# DA14682 register map
Vendor: Dialog; Series: DA14682; File version: 1.2
CPU: CM0 r1p0, little endian, MPU, FPU, 3 interrupt priority bits
Registers are 16-bit, read-write, reset 0x0 unless marked. A register's access mark holds for its fields unless they carry their own. Offsets are from the block's base; [hi:lo] are bit positions; {n}, {i} and the like mark numbered series.

## BLE — BLE registers
Base 0x40000000
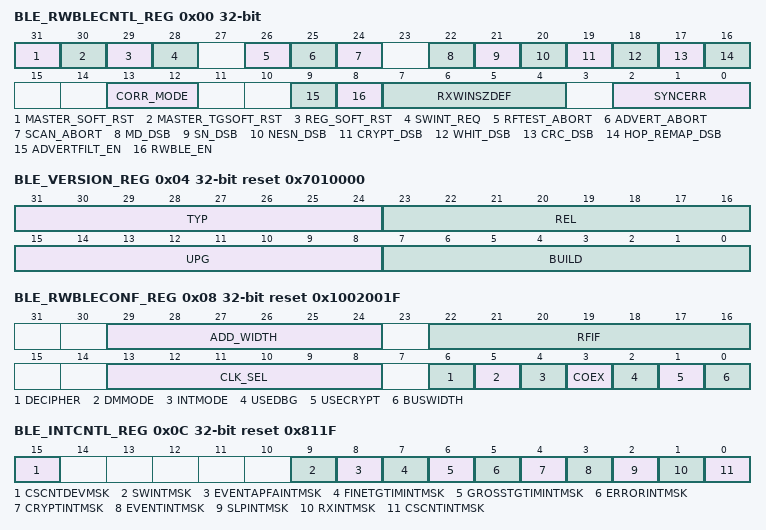
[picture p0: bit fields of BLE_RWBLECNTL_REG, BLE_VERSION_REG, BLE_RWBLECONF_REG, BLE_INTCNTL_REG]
0x00 BLE_RWBLECNTL_REG 32-bit (reset mask 0x7FFFFFFF) — BLE Control register
  [31] MASTER_SOFT_RST wo — Reset the complete BLE Core except registers and timing generator, when written with a 1. Resets at 0 when action is performed. No action happens if it is written with 0.
  [30] MASTER_TGSOFT_RST wo — Reset the timing generator, when written with a 1. Resets at 0 when action is performed. No action happens if it is written with 0.
  [29] REG_SOFT_RST — Reset the complete register block, when written with a 1. Resets at 0 when action is performed. No action happens if it is written with 0. Note that INT STAT will not be cleared, so the user should also write to BLE_INTACK_REG after the SW Reset
  [28] SWINT_REQ wo — Forces the generation of ble_sw_irq when written with a 1, and proper masking is set. Resets at 0 when action is performed. No action happens if it is written with 0.
  [26] RFTEST_ABORT wo — Abort the current RF Testing defined as per CS-FORMAT when written with a 1. Resets at 0 when action is performed. No action happens if it is written with 0. Note that when RFTEST_ABORT is requested: 1) In case of infinite Tx, the Packet Controller FSM stops at the end of the current byte in process, and processes accordingly the packet CRC. 2) In case of Infinite Rx, the Packet Controller FSM either stops as the end of the current Packet reception (if Access address has been detected), or simply stop the processing switching off the RF.
  [25] ADVERT_ABORT wo — Abort the current Advertising event when written with a 1. Resets at 0 when action is performed. No action happens if it is written with 0.
  [24] SCAN_ABORT wo — Abort the current scan window when written with a 1. Resets at 0 when action is performed. No action happens if it is written with 0.
  [22] MD_DSB — 0: Normal operation of MD bits management 1: Allow a single Tx/Rx exchange whatever the MD bits are. value forced by SW from Tx Descriptorvalue just saved in Rx Descriptor during reception
  [21] SN_DSB — 0: Normal operation of Sequence number 1: Sequence Number Management disabled: value forced by SW from Tx Descriptorvalue ignored in Rx, where no SN error reported.
  [20] NESN_DSB — 0: Normal operation of Acknowledge 1: Acknowledge scheme disabled: value forced by SW from Tx Descriptorvalue ignored in Rx, where no NESN error reported.
  [19] CRYPT_DSB — 0: Normal operation. Encryption / Decryption enabled. 1: Encryption / Decryption disabled. Note that if CS-CRYPT_EN is set, then MIC is generated, and only data encryption is disabled, meaning data sent are plain data.
  [18] WHIT_DSB — 0: Normal operation. Whitening enabled. 1: Whitening disabled.
  [17] CRC_DSB — 0: Normal operation. CRC removed from data stream. 1: CRC stripping disabled on Rx packets, CRC replaced by 0x000 in Tx.
  [16] HOP_REMAP_DSB — 0: Normal operation. Frequency Hopping Remapping algorithm enabled. 1: Frequency Hopping Remapping algorithm disabled
  [13:12] CORR_MODE — Defines correlation mode 00: Correlates onto Access Address 01: Correlates onto half preamble and Access Address 10: Correlates onto full preamble and Access Address 11: n/a
  [9] ADVERTFILT_EN — Advertising Channels Error Filtering Enable control 0: RW-BLE Core reports all errors to RW-BLE Software 1: RW-BLE Core reports only correctly received packet, without error to RW-BLE Software
  [8] RWBLE_EN — 0: Disable RW-BLE Core Exchange Table pre-fetch mechanism. 1: Enable RW-BLE Core Exchange table pre-fetch mechanism.
  [7:4] RXWINSZDEF — Default Rx Window size in us. Used when device: is master connectedperforms its second receipt.0 is not a valid value. Recommended value is 10 (in decimal).
  [2:0] SYNCERR — Indicates the maximum number of errors allowed to recognize the synchronization word.
0x04 BLE_VERSION_REG 32-bit reset 0x7010000 (reset mask 0x7FFFFFFF) — Version register
  [31:24] TYP ro — BLE Core Type
  [23:16] REL ro — BLE Core version Major release number.
  [15:8] UPG ro — BLE Core upgrade Upgrade number.
  [7:0] BUILD ro — BLE Core Build Build number.
0x08 BLE_RWBLECONF_REG 32-bit reset 0x1002001F — Configuration register
  [29:24] ADD_WIDTH ro — Value of the RW_BLE_ADDRESS_WIDTH parameter concerted into binary.
  [22:16] RFIF ro — Radio Interface ID
  [13:8] CLK_SEL ro — Operating Frequency (in MHz)
  [6] DECIPHER ro — 0: AES deciphering not present
  [5] DMMODE ro — 0: RW-BLE Core is used as a standalone BLE device
  [4] INTMODE ro — 1: Interrupts are trigger level generated, i.e. stays active at 1 till acknowledgement
  [3] COEX ro — 1: WLAN Coexistence mechanism present
  [2] USEDBG ro — 1: Diagnostic port instantiated
  [1] USECRYPT ro — 1: AES-CCM Encryption block present
  [0] BUSWIDTH ro — Processor bus width: 1: 32 bits
0x0C BLE_INTCNTL_REG 32-bit reset 0x811F — Interrupt controller register
  [15] CSCNTDEVMSK — CSCNT interrupt mask during event. This bit allows to enable CSCNT interrupt generation during events (i.e. advertising, scanning, initiating, and connection) 0: CSCNT Interrupt not generated during events. 1: CSCNT Interrupt generated during events.
  [9] SWINTMSK — SW triggered interrupt Mask 0: Interrupt not generated 1: Interrupt generated
  [8] EVENTAPFAINTMSK — End of event / anticipated pre-fetch abort interrupt Mask 0: Interrupt not generated 1: Interrupt generated
  [7] FINETGTIMINTMSK — Fine Target Timer Mask 0: Interrupt not generated 1: Interrupt generated
  [6] GROSSTGTIMINTMSK — Gross Target Timer Mask 0: Interrupt not generated 1: Interrupt generated
  [5] ERRORINTMSK — Error Interrupt Mask 0: Interrupt not generated 1: Interrupt generated
  [4] CRYPTINTMSK — Encryption engine Interrupt Mask 0: Interrupt not generated 1: Interrupt generated
  [3] EVENTINTMSK — End of event Interrupt Mask 0: Interrupt not generated 1: Interrupt generated
  [2] SLPINTMSK — Sleep Mode Interrupt Mask 0: Interrupt not generated 1: Interrupt generated
  [1] RXINTMSK — Rx Interrupt Mask 0: Interrupt not generated 1: Interrupt generated
  [0] CSCNTINTMSK — 625us Base Time Interrupt Mask 0: Interrupt not generated 1: Interrupt generated
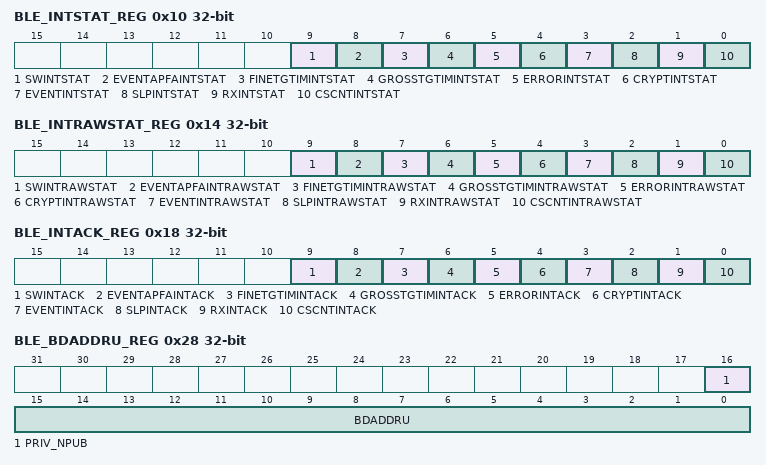
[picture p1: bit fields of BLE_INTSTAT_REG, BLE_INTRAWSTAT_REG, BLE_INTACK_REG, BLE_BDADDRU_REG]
0x10 BLE_INTSTAT_REG 32-bit — Interrupt status register
  [9] SWINTSTAT ro — SW triggered interrupt status 0: No SW triggered interrupt. 1: A SW triggered interrupt is pending
  [8] EVENTAPFAINTSTAT ro — End of event / Anticipated Pre-Fetch Abort interrupt status 0: No End of Event interrupt. 1: An End of Event interrupt is pending.
  [7] FINETGTIMINTSTAT ro — Masked Fine Target Timer Error interrupt status 0: No Fine Target Timer interrupt. 1: A Fine Target Timer interrupt is pending.
  [6] GROSSTGTIMINTSTAT ro — Masked Gross Target Timer interrupt status 0: No Gross Target Timer interrupt. 1: A Gross Target Timer interrupt is pending.
  [5] ERRORINTSTAT ro — Masked Error interrupt status 0: No Error interrupt. 1: An Error interrupt is pending.
  [4] CRYPTINTSTAT ro — Masked Encryption engine interrupt status 0: No Encryption / Decryption interrupt. 1: An Encryption / Decryption interrupt is pending.
  [3] EVENTINTSTAT ro — Masked End of Event interrupt status 0: No End of Advertising / Scanning / Connection interrupt. 1: An End of Advertising / Scanning / Connection interrupt is pending.
  [2] SLPINTSTAT ro — Masked Sleep interrupt status 0: No End of Sleep Mode interrupt. 1: An End of Sleep Mode interrupt is pending.
  [1] RXINTSTAT ro — Masked Packet Reception interrupt status 0: No Rx interrupt. 1: An Rx interrupt is pending.
  [0] CSCNTINTSTAT ro — Masked 625us base time reference interrupt status 0: No 625us Base Time interrupt. 1: A 625us Base Time interrupt is pending.
0x14 BLE_INTRAWSTAT_REG 32-bit — Interrupt raw status register
  [9] SWINTRAWSTAT ro — SW triggered interrupt raw status 0: No SW triggered interrupt. 1: A SW triggered interrupt is pending.
  [8] EVENTAPFAINTRAWSTAT ro — End of event / Anticipated Pre-Fetch Abort interrupt raw status 0: No End of Event interrupt. 1: An End of Event interrupt is pending.
  [7] FINETGTIMINTRAWSTAT ro — Fine Target Timer Error interrupt raw status 0: No Fine Target Timer interrupt. 1: A Fine Target Timer interrupt is pending.
  [6] GROSSTGTIMINTRAWSTAT ro — Gross Target Timer interrupt raw status 0: No Gross Target Timer interrupt. 1: A Gross Target Timer interrupt is pending.
  [5] ERRORINTRAWSTAT ro — Error interrupt raw status 0: No Error interrupt. 1: An Error interrupt is pending.
  [4] CRYPTINTRAWSTAT ro — Encryption engine interrupt raw status 0: No Encryption / Decryption interrupt. 1: An Encryption / Decryption interrupt is pending.
  [3] EVENTINTRAWSTAT ro — End of Event interrupt raw status 0: No End of Advertising / Scanning / Connection interrupt. 1: An End of Advertising / Scanning / Connection interrupt is pending.
  [2] SLPINTRAWSTAT ro — Sleep interrupt raw status 0: No End of Sleep Mode interrupt. 1: An End of Sleep Mode interrupt is pending.
  [1] RXINTRAWSTAT ro — Packet Reception interrupt raw status 0: No Rx interrupt. 1: An Rx interrupt is pending.
  [0] CSCNTINTRAWSTAT ro — 625us base time reference interrupt raw status 0: No 625us Base Time interrupt. 1: A 625us Base Time interrupt is pending.
0x18 BLE_INTACK_REG 32-bit — Interrupt acknowledge register
  [9] SWINTACK wo — SW triggered interrupt acknowledgement bit Software writing 1 acknowledges the SW triggered interrupt. This bit resets SWINTSTAT and SWINTRAWSTAT flags. Resets at 0 when action is performed
  [8] EVENTAPFAINTACK wo — End of event / Anticipated Pre-Fetch Abort interrupt acknowledgement bit Software writing 1 acknowledges the End of event / Anticipated Pre-Fetch Abort interrupt. This bit resets EVENTAPFAINTSTAT and EVENTAPFAINTRAWSTAT flags. Resets at 0 when action is performed
  [7] FINETGTIMINTACK wo — Fine Target Timer interrupt acknowledgement bit Software writing 1 acknowledges the Fine Timer interrupt. This bit resets FINETGTIMINTSTAT and FINETGTIMINTRAWSTAT flags. Resets at 0 when action is performed
  [6] GROSSTGTIMINTACK wo — Gross Target Timer interrupt acknowledgement bit Software writing 1 acknowledges the Gross Timer interrupt. This bit resets GROSSTGTIMINTSTAT and GROSSTGTIMINTRAWSTAT flags. Resets at 0 when action is performed
  [5] ERRORINTACK wo — Error interrupt acknowledgement bit Software writing 1 acknowledges the Error interrupt. This bit resets ERRORINTSTAT and ERRORINTRAWSTAT flags. Resets at 0 when action is performed
  [4] CRYPTINTACK wo — Encryption engine interrupt acknowledgement bit Software writing 1 acknowledges the Encryption engine interrupt. This bit resets CRYPTINTSTAT and CRYPTINTRAWSTAT flags. Resets at 0 when action is performed
  [3] EVENTINTACK wo — End of Event interrupt acknowledgment bit Software writing 1 acknowledges the End of Advertising / Scanning / Connection interrupt. This bit resets SLPINTSTAT and SLPINTRAWSTAT flags. Resets at 0 when action is performed
  [2] SLPINTACK wo — End of Deep Sleep interrupt acknowledgment bit Software writing 1 acknowledges the End of Sleep Mode interrupt. This bit resets SLPINTSTAT and SLPINTRAWSTAT flags. Resets at 0 when action is performed
  [1] RXINTACK wo — Packet Reception interrupt acknowledgment bit Software writing 1 acknowledges the Rx interrupt. This bit resets RXINTSTAT and RXINTRAWSTAT flags. Resets at 0 when action is performed
  [0] CSCNTINTACK wo — 625us base time reference interrupt acknowledgment bit Software writing 1 acknowledges the CLKN interrupt. This bit resets CLKINTSTAT and CLKINTRAWSTAT flags. Resets at 0 when action is performed
0x1C BLE_BASETIMECNT_REG 32-bit — Base time reference counter
  [26:0] BASETIMECNT ro — Value of the 625us base time reference counter. Updated each time SAMPCLK is written. Used by the SW in order to synchronize with the HW
0x20 BLE_FINETIMECNT_REG 32-bit — Fine time reference counter
  [9:0] FINECNT ro — Value of the current s fine time reference counter. Updated each time SAMPCLK is written. Used by the SW in order to synchronize with the HW, and obtain a more precise sleep duration
0x24 BLE_BDADDRL_REG 32-bit (reset mask 0x7FFFFFFF) — BLE device address LSB register
  [31:0] BDADDRL — Bluetooth Low Energy Device Address. LSB part.
0x28 BLE_BDADDRU_REG 32-bit — BLE device address MSB register
  [16] PRIV_NPUB — Bluetooth Low Energy Device Address privacy indicator 0: Public Bluetooth Device Address 1: Private Bluetooth Device Address
  [15:0] BDADDRU — Bluetooth Low Energy Device Address. MSB part.
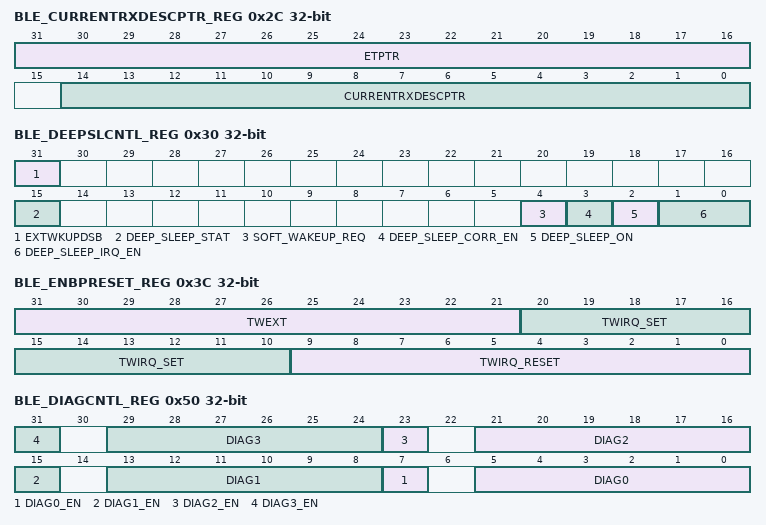
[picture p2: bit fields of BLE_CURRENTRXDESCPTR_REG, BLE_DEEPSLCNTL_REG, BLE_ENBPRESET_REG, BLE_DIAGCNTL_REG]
0x2C BLE_CURRENTRXDESCPTR_REG 32-bit (reset mask 0x7FFFFFFF) — Rx Descriptor Pointer for the Receive Buffer Chained List
  [31:16] ETPTR — Exchange Table Pointer that determines the starting point of the Exchange Table
  [14:0] CURRENTRXDESCPTR — Rx Descriptor Pointer that determines the starting point of the Receive Buffer Chained List
0x30 BLE_DEEPSLCNTL_REG 32-bit (reset mask 0x7FFFFFFF) — Deep-Sleep control register
  [31] EXTWKUPDSB — External Wake-Up disable 0: RW-BLE Core can be woken by external wake-up 1: RW-BLE Core cannot be woken up by external wake-up
  [15] DEEP_SLEEP_STAT ro — Indicator of current Deep Sleep clock mux status: 0: RW-BLE Core is not yet in Deep Sleep Mode 1: RW-BLE Core is in Deep Sleep Mode (only low_power_clk is running)
  [4] SOFT_WAKEUP_REQ — Wake Up Request from RW-BLE Software. Applies when system is in Deep Sleep Mode. It wakes up the RW-BLE Core when written with a 1. Resets at 0 when action is performed. No action happens if it is written with 0.
  [3] DEEP_SLEEP_CORR_EN — 625us base time reference integer and fractional part correction. Applies when system has been woken-up from Deep Sleep Mode. It enables Fine Counter and Base Time counter when written with a 1. Resets at 0 when action is performed. No action happens if it is written with 0.
  [2] DEEP_SLEEP_ON — 0: RW-BLE Core in normal active mode 1: Request RW-BLE Core to switch in deep sleep mode. This bit is reset on DEEP_SLEEP_STAT falling edge.
  [1:0] DEEP_SLEEP_IRQ_EN — Always set to "3" when DEEP_SLEEP_ON is set to "1". It controls the generation of BLE_WAKEUP_LP_IRQ.
0x34 BLE_DEEPSLWKUP_REG 32-bit (reset mask 0x7FFFFFFF) — Time (measured in Low Power clock cycles) in Deep Sleep Mode before waking-up the device
  [31:0] DEEPSLTIME — Determines the time in low_power_clk clock cycles to spend in Deep Sleep Mode before waking-up the device. This ensures a maximum of 37 hours and 16mn sleep mode capabilities at 32kHz. This ensures a maximum of 36 hours and 16mn sleep mode capabilities at 32.768kHz
0x38 BLE_DEEPSLSTAT_REG 32-bit (reset mask 0x7FFFFFFF) — Duration of the last deep sleep phase register
  [31:0] DEEPSLDUR ro — Actual duration of the last deep sleep phase measured in low_power_clk clock cycle. DEEPSLDUR is set to zero at the beginning of the deep sleep phase, and is incremented at each low_power_clk clock cycle until the end of the deep sleep phase.
0x3C BLE_ENBPRESET_REG 32-bit (reset mask 0x7FFFFFFF) — Time in low power oscillator cycles register
  [31:21] TWEXT — Minimum and recommended value is "TWIRQ_RESET + 1". In the case of wake-up due to an external wake-up request, TWEXT specifies the time delay in low power oscillator cycles to deassert BLE_WAKEUP_LP_IRQ. Refer also to GP_CONTROL_REG[BLE_WAKEUP_REQ]. Range is [0...64 ms] for 32kHz; [0...62.5 ms] for 32.768kHz
  [20:10] TWIRQ_SET — Minimum value is "TWIRQ_RESET + 1". Time in low power oscillator cycles to set BLE_WAKEUP_LP_IRQ before the BLE sleep timer expiration. Refer also to BLE_DEEPSLWKUP_REG[DEEPSLTIME]. Range is [0...64 ms] for 32kHz; [0...62.5 ms] for 32.768kHz
  [9:0] TWIRQ_RESET — Recommended value is 1. Time in low power oscillator cycles to reset BLE_WAKEUP_LP_IRQ before the BLE sleep timer expiration. Refer also to BLE_DEEPSLWKUP_REG[DEEPSLTIME]. Range is [0...32 ms] for 32kHz; [0...31.25 ms] for 32.768kHz.
0x40 BLE_FINECNTCORR_REG 32-bit — Phase correction value register
  [9:0] FINECNTCORR — Phase correction value for the 625us reference counter (i.e. Fine Counter) in us.
0x44 BLE_BASETIMECNTCORR_REG 32-bit — Base Time Counter
  [26:0] BASETIMECNTCORR — Base Time Counter correction value.
0x50 BLE_DIAGCNTL_REG 32-bit (reset mask 0x7FFFFFFF) — Diagnostics Register
  [8n+7] DIAG{n}_EN (n=0..3) — 0: Disable diagnostic port 0 output. All outputs are set to 0x0. 1: Enable diagnostic port 0 output.
  [8n+5:8n] DIAG{n} (n=0..3) — Only relevant when DIAG{n}_EN = 1. Selection of the outputs that must be driven to the diagnostic port BLE_DIAG{n}.
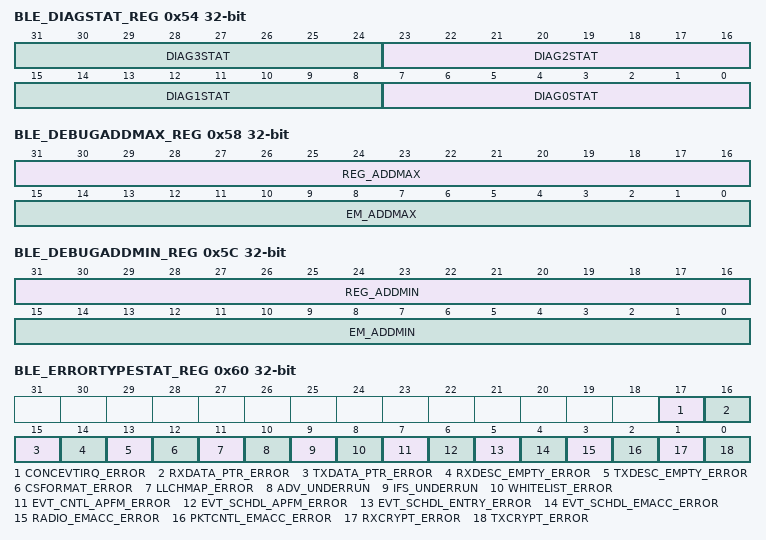
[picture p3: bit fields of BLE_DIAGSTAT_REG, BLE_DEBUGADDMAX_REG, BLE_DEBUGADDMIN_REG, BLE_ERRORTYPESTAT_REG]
0x54 BLE_DIAGSTAT_REG 32-bit (reset mask 0x7FFFFFFF) — Debug use only
  [8n+7:8n] DIAG{n}STAT ro (n=0..3) — Directly connected to ble_dbg{n}[7:0] output. Debug use only.
0x58 BLE_DEBUGADDMAX_REG 32-bit (reset mask 0x7FFFFFFF) — Upper limit for the memory zone
  [31:16] REG_ADDMAX — Upper limit for the Register zone indicated by the reg_inzone flag
  [15:0] EM_ADDMAX — Upper limit for the Exchange Memory zone indicated by the em_inzone flag
0x5C BLE_DEBUGADDMIN_REG 32-bit (reset mask 0x7FFFFFFF) — Lower limit for the memory zone
  [31:16] REG_ADDMIN — Lower limit for the Register zone indicated by the reg_inzone flag
  [15:0] EM_ADDMIN — Lower limit for the Exchange Memory zone indicated by the em_inzone flag
0x60 BLE_ERRORTYPESTAT_REG 32-bit — Error Type Status registers
  [17] CONCEVTIRQ_ERROR ro — Indicates whether two consecutive and concurrent ble_event_irq have been generated, and not acknowledged in time by the RW-BLE Software. 0: No error 1: Error occurred
  [16] RXDATA_PTR_ERROR ro — Indicates whether Rx data buffer pointer value programmed is null: this is a major programming failure. 0: No error 1: Error occurred
  [15] TXDATA_PTR_ERROR ro — Indicates whether Tx data buffer pointer value programmed is null during Advertising / Scanning / Initiating events, or during Master / Slave connections with non-null packet length: this is a major programming failure. 0: No error 1: Error occurred
  [14] RXDESC_EMPTY_ERROR ro — Indicates whether Rx Descriptor pointer value programmed in register is null: this is a major programming failure. 0: No error 1: Error occurred
  [13] TXDESC_EMPTY_ERROR ro — Indicates whether Tx Descriptor pointer value programmed in Control Structure is null during Advertising / Scanning / Initiating events: this is a major programming failure. 0: No error 1: Error occurred
  [12] CSFORMAT_ERROR ro — Indicates whether CS-FORMAT has been programmed with an invalid value: this is a major software programming failure. 0: No error 1: Error occurred
  [11] LLCHMAP_ERROR ro — Indicates Link Layer Channel Map error, happens when actual number of CS-LLCHMAP bit set to one is different from CS-NBCHGOOD at the beginning of Frequency Hopping process 0: No error 1: Error occurred
  [10] ADV_UNDERRUN ro — Indicates Advertising Interval Under run, occurs if time between two consecutive Advertising packet (in Advertising mode) is lower than the expected value. 0: No error 1: Error occurred
  [9] IFS_UNDERRUN ro — Indicates Inter Frame Space Under run, occurs if IFS time is not enough to update and read Control Structure/Descriptors, and/or White List parsing is not finished and/or Decryption time is too long to be finished on time 0: No error 1: Error occurred
  [8] WHITELIST_ERROR ro — Indicates White List Timeout error, occurs if White List parsing is not finished on time 0: No error 1: Error occurred
  [7] EVT_CNTL_APFM_ERROR ro — Indicates Anticipated Pre-Fetch Mechanism error: happens when 2 consecutive events are programmed, and when the first event is not completely finished while second pre-fetch instant is reached. 0: No error 1: Error occured
  [6] EVT_SCHDL_APFM_ERROR ro — Indicates Anticipated Pre-Fetch Mechanism error: happens when 2 consecutive events are programmed, and when the first event is not completely finished while second pre-fetch instant is reached. 0: No error 1: Error occured
  [5] EVT_SCHDL_ENTRY_ERROR ro — Indicates Event Scheduler faced Invalid timing programing on two consecutive ET entries (e.g first one with 624s offset and second one with no offset) 0: No error 1: Error occurred
  [4] EVT_SCHDL_EMACC_ERROR ro — Indicates Event Scheduler Exchange Memory access error, happens when Exchange Memory accesses are not served in time, and blocks the Exchange Table entry read 0: No error 1: Error occurred
  [3] RADIO_EMACC_ERROR ro — Indicates Radio Controller Exchange Memory access error, happens when Exchange Memory accesses are not served in time and data are corrupted. 0: No error 1: Error occurred
  [2] PKTCNTL_EMACC_ERROR ro — Indicates Packet Controller Exchange Memory access error, happens when Exchange Memory accesses are not served in time and Tx/Rx data are corrupted 0: No error 1: Error occurred
  [1] RXCRYPT_ERROR ro — Indicates real time decryption error, happens when AES-CCM decryption is too slow compared to Packet Controller requests. A 16-bytes block has to be decrypted prior the next block is received by the Packet Controller 0: No error 1: Error occurred
  [0] TXCRYPT_ERROR ro — Indicates Real Time encryption error, happens when AES-CCM encryption is too slow compared to Packet Controller requests. A 16-bytes block has to be encrypted and prepared on Packet Controller request, and needs to be ready before the Packet Controller has to send ti 0: No error 1: Error occurred
0x64 BLE_SWPROFILING_REG 32-bit (reset mask 0x7FFFFFFF) — Software Profiling register
  [31:0] SWPROFVAL — Software Profiling register: used by RW-BLE Software for profiling purpose: this value is copied on Diagnostic port
0x70 BLE_RADIOCNTL0_REG 32-bit reset 0x2 — Radio interface control register
  [4:2] field246rsv
0x74 BLE_RADIOCNTL1_REG 32-bit — Radio interface control register
  [20:16] XRFSEL — Extended radio selection field, Must be set to "2".
0x78 BLE_RADIOCNTL2_REG 32-bit (reset mask 0x7FFFFFFF) — Radio interface control register
0x7C BLE_RADIOCNTL3_REG 32-bit reset 0x40 (reset mask 0x7FFFFFFF) — Radio interface control register
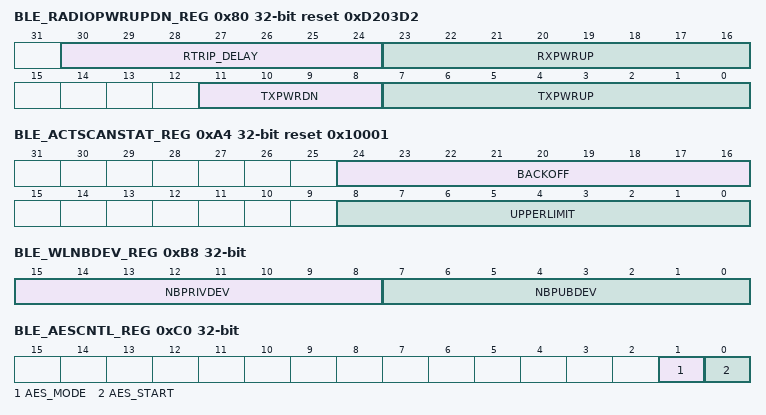
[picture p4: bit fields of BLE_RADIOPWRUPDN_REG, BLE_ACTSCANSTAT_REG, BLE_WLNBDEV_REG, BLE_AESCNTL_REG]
0x80 BLE_RADIOPWRUPDN_REG 32-bit reset 0xD203D2 — RX/TX power up/down phase register
  [30:24] RTRIP_DELAY — Defines round trip delay value. This value correspond to the addition of data latency in Tx and data latency in Rx. Value is in us
  [23:16] RXPWRUP — This register holds the length in s of the RX power up phase for the current radio device. Default value is 210us (reset value). Operating range depends on the selected radio.
  [11:8] TXPWRDN — This register extends the length in s of the TX power down phase for the current radio device. Default value is 3us (reset value). Operating range depends on the selected radio.
  [7:0] TXPWRUP — This register holds the length in s of the TX power up phase for the current radio device. Default value is 210us (reset value). Operating range depends on the selected radio.
0x90 BLE_ADVCHMAP_REG 32-bit reset 0x7 — Advertising Channel Map
  [2:0] ADVCHMAP — Advertising Channel Map, defined as per the advertising connection settings. Contains advertising channels index 37 to 39. If ADVCHMAP[i] equals: 0: Do not use data channel i+37. 1: Use data channel i+37.
0xA0 BLE_ADVTIM_REG 32-bit — Advertising Packet Interval
  [13:0] ADVINT — Advertising Packet Interval defines the time interval in between two ADV_xxx packet sent. Value is in us. Value to program depends on the used Advertising Packet type and the device filtering policy.
0xA4 BLE_ACTSCANSTAT_REG 32-bit reset 0x10001 — Active scan register
  [24:16] BACKOFF ro — Active scan mode back-off counter initialization value.
  [8:0] UPPERLIMIT ro — Active scan mode upper limit counter value.
0xB0 BLE_WLPUBADDPTR_REG 32-bit — Start address of public devices list
  [15:0] WLPUBADDPTR — Start address pointer of the public devices white list.
0xB4 BLE_WLPRIVADDPTR_REG 32-bit — Start address of private devices list
  [15:0] WLPRIVADDPTR — Start address pointer of the private devices white list.
0xB8 BLE_WLNBDEV_REG 32-bit — Devices in white list
  [15:8] NBPRIVDEV — Number of private devices in the white list.
  [7:0] NBPUBDEV — Number of public devices in the white list.
0xC0 BLE_AESCNTL_REG 32-bit — Start AES register
  [1] AES_MODE — 0: Cipher mode 1: Decipher mode
  [0] AES_START wo — Writing a 1 starts AES-128 ciphering/deciphering process. This bit is reset once the process is finished (i.e. ble_crypt_irq interrupt occurs, even masked)
0xC4 BLE_AESKEY31_0_REG 32-bit (reset mask 0x7FFFFFFF) — AES encryption key
  [31:0] AESKEY31_0 — AES encryption 128-bit key. Bit 31 down to 0
0xC8 BLE_AESKEY63_32_REG 32-bit (reset mask 0x7FFFFFFF) — AES encryption key
  [31:0] AESKEY63_32 — AES encryption 128-bit key. Bit 63 down to 32
0xCC BLE_AESKEY95_64_REG 32-bit (reset mask 0x7FFFFFFF) — AES encryption key
  [31:0] AESKEY95_64 — AES encryption 128-bit key. Bit 95 down to 64
0xD0 BLE_AESKEY127_96_REG 32-bit (reset mask 0x7FFFFFFF) — AES encryption key
  [31:0] AESKEY127_96 — AES encryption 128-bit key. Bit 127 down to 96
0xD4 BLE_AESPTR_REG 32-bit — Pointer to the block to encrypt/decrypt
  [15:0] AESPTR — Pointer to the memory zone where the block to cipher/decipher using AES-128 is stored.
0xD8 BLE_TXMICVAL_REG 32-bit (reset mask 0x7FFFFFFF) — AES / CCM plain MIC value
  [31:0] TXMICVAL ro — AES-CCM plain MIC value. Valid on when MIC has been calculated (in Tx)
0xDC BLE_RXMICVAL_REG 32-bit (reset mask 0x7FFFFFFF) — AES / CCM plain MIC value
  [31:0] RXMICVAL ro — AES-CCM plain MIC value. Valid on once MIC has been extracted from Rx packet.
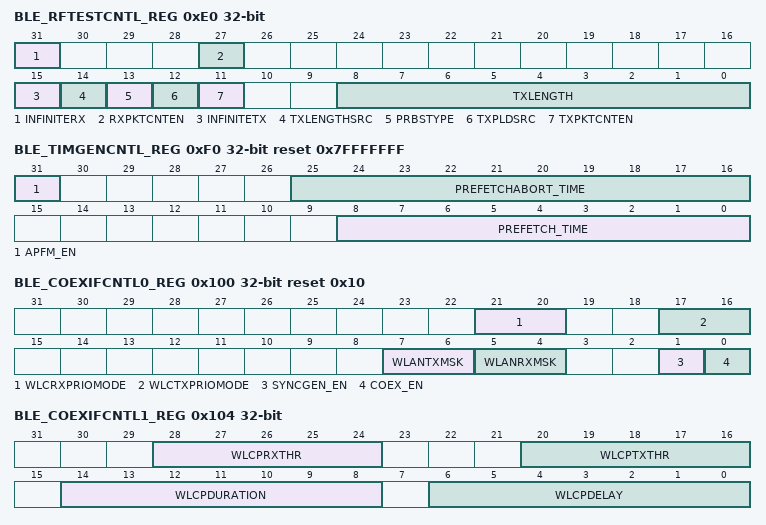
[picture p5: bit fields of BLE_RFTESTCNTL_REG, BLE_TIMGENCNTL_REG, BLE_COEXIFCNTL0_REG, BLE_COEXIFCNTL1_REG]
0xE0 BLE_RFTESTCNTL_REG 32-bit (reset mask 0x7FFFFFFF) — RF Testing Register
  [31] INFINITERX — Applicable in RF Test Mode only 0: Normal mode of operation 1: Infinite Rx window
  [27] RXPKTCNTEN — Applicable in RF Test Mode only 0: Rx packet count disabled 1: Rx packet count enabled, and reported in CS-RXCCMPKTCNT and RFTESTRXSTAT-RXPKTCNT on RF abort command
  [15] INFINITETX — Applicable in RF Test Mode only 0: Normal mode of operation. 1: Infinite Tx packet / Normal start of a packet but endless payload
  [14] TXLENGTHSRC — Applicable only in Tx/Rx RF Test mode 0: Normal mode of operation: TxDESC-TXADVLEN controls the Tx packet payload size 1: Uses RFTESTCNTL-TXLENGTH packet length (can support up to 512 bytes transmit)
  [13] PRBSTYPE — Applicable only in Tx/Rx RF Test mode 0: Tx Packet Payload are PRBS9 type 1: Tx Packet Payload are PRBS15 type
  [12] TXPLDSRC — Applicable only in Tx/Rx RF Test mode 0: Tx Packet Payload source is the Control Structure 1: Tx Packet Payload are PRBS generator
  [11] TXPKTCNTEN — Applicable in RF Test Mode only 0: Tx packet count disabled 1: Tx packet count enabled, and reported in CS-TXCCMPKTCNT and RFTESTTXSTAT-TXPKTCNT on RF abort command
  [8:0] TXLENGTH — Applicable only for Tx/Rx RF Test mode, and valid when RFTESTCNTL-TXLENGTHSRC = 1 Tx packet length in number of byte
0xE4 BLE_RFTESTTXSTAT_REG 32-bit (reset mask 0x7FFFFFFF) — RF Testing Register
  [31:0] TXPKTCNT ro — Reports number of transmitted packet during Test Modes. Value is valid if RFTESTCNTL-TXPKTCNTEN is set
0xE8 BLE_RFTESTRXSTAT_REG 32-bit (reset mask 0x7FFFFFFF) — RF Testing Register
  [31:0] RXPKTCNT ro — Reports number of correctly received packet during Test Modes (no sync error, no CRC error). Value is valid if RFTESTCNTL-RXPKTCNTEN is set
0xF0 BLE_TIMGENCNTL_REG 32-bit reset 0x7FFFFFFF (reset mask 0x7FFFFFFF) — Timing Generator Register
  [31] APFM_EN — Controls the Anticipated pre-Fetch Abort mechanism 0: Disabled 1: Enabled
  [25:16] PREFETCHABORT_TIME — Defines the instant in s at which immediate abort is required after anticipated pre-fetch abort
  [8:0] PREFETCH_TIME — Defines Exchange Table pre-fetch instant in us
0xF4 BLE_GROSSTIMTGT_REG 32-bit — Gross Timer Target value
  [22:0] GROSSTARGET — Gross Timer Target value on which a ble_grosstgtim_irq must be generated. This timer has a precision of 10ms: interrupt is generated only when GROSSTARGET[22:0] = BASETIMECNT[26:4] and BASETIMECNT[3:0] = 0.
0xF8 BLE_FINETIMTGT_REG 32-bit — Fine Timer Target value
  [26:0] FINETARGET — Fine Timer Target value on which a ble_finetgtim_irq must be generated. This timer has a precision of 625us: interrupt is generated only when FINETARGET = BASETIMECNT
0xFC BLE_SAMPLECLK_REG 32-bit — Samples the Base Time Counter
  [0] SAMP wo — Writing a 1 samples the Base Time Counter value in BASETIMECNT register. Resets at 0 when action is performed.
0x100 BLE_COEXIFCNTL0_REG 32-bit reset 0x10 — Coexistence interface Control 0 Register
  [21:20] WLCRXPRIOMODE — Defines Bluetooth Low Energy packet ble_rx mode behavior. 00: Rx indication excluding Rx Power up delay (starts when correlator is enabled) 01: Rx indication including Rx Power up delay 10: Rx High priority indicator 11: n/a
  [17:16] WLCTXPRIOMODE — Defines Bluetooth Low Energy packet ble_tx mode behavior 00: Tx indication excluding Tx Power up delay 01: Tx indication including Tx Power up delay 10: Tx High priority indicator 11: n/a
  [7:6] WLANTXMSK — Determines how wlan_tx impact BLE Tx and Rx 00: wlan_tx has no impact (default mode) 01: wlan_tx can stop BLE Tx, no impact on BLE Rx 10: wlan_tx can stop BLE Rx, no impact on BLE Tx 11: wlan_tx can stop both BLE Tx and BLE Rx
  [5:4] WLANRXMSK — Determines how wlan_rx impact BLE Tx and Rx 00: wlan_rx has no impact 01: wlan_rx can stop BLE Tx, no impact on BLE Rx (default mode) 10: wlan_rx can stop BLE Rx, no impact on BLE Tx 11: wlan_rx can stop both BLE Tx and BLE Rx
  [1] SYNCGEN_EN — Determines whether ble_sync is generated or not. 0: ble_sync pulse not generated 1: ble_sync pulse generated
  [0] COEX_EN — Enable / Disable control of the MWS/WLAN Coexistence control 0: Coexistence interface disabled 1: Coexistence interface enabled
0x104 BLE_COEXIFCNTL1_REG 32-bit — Coexistence interface Control 1 Register
  [28:24] WLCPRXTHR — Applies on ble_rx if WLCRXPRIOMODE equals 10 Determines the threshold for Rx priority setting. If ble_pti[3:0] output value is greater than WLCPRXTHR, then Rx Bluetooth Low Energy priority is considered as high, and must be provided to the WLAN coexistence interface
  [20:16] WLCPTXTHR — Applies on ble_tx if WLCTXPRIOMODE equals 10 Determines the threshold for priority setting. If ble_pti[3:0] output value is greater than WLCPTXTHR, then Tx Bluetooth Low Energy priority is considered as high, and must be provided to the WLAN coexistence interface
  [14:8] WLCPDURATION — Applies on ble_tx if WLCTXPRIOMODE equals 10 Applies on ble_rx if WLCRXPRIOMODE equals 10 Determines how many s the priority information must be maintained Note that if WLCPDURATION = 0x00, then Tx/Rx priority levels are maintained till Tx/Rx EN are de-asserted.
  [6:0] WLCPDELAY — Applies on ble_tx if WLCTXPRIOMODE equals 10. Applies on ble_rx if WLCRXPRIOMODE equals 10. Determines the delay (in us) in Tx/Rx enables rises the time Bluetooth Low energy Tx/Rx priority has to be provided .
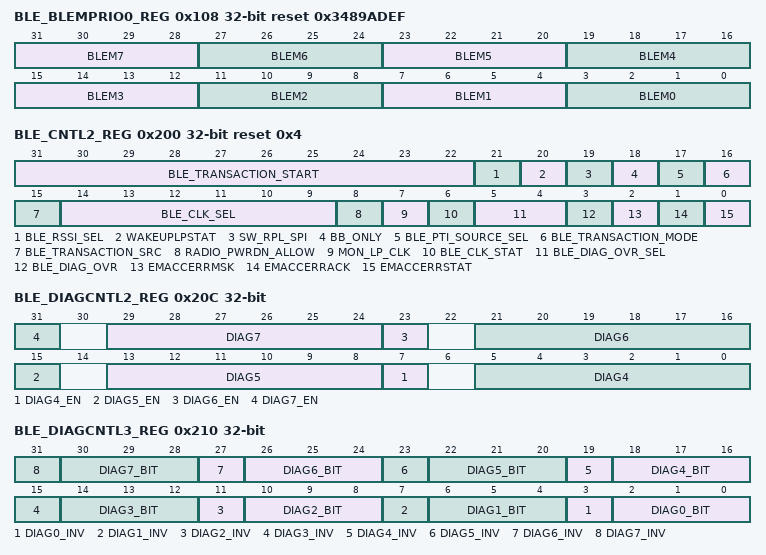
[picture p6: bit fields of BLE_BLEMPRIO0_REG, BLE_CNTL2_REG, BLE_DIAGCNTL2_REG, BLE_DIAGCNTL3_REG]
0x108 BLE_BLEMPRIO0_REG 32-bit reset 0x3489ADEF (reset mask 0x7FFFFFFF) — Coexistence interface Priority 0 Register
  [31:28] BLEM7 — Set Priority value for Passive Scanning
  [27:24] BLEM6 — Set Priority value for Non-Connectable Advertising
  [23:20] BLEM5 — Set Priority value for Connectable Advertising BLE message
  [19:16] BLEM4 — Set Priority value for Active Scanning BLE message
  [15:12] BLEM3 — Set Priority value for Initiating (Scanning) BLE message
  [11:8] BLEM2 — Set Priority value for Data Channel transmission BLE message
  [7:4] BLEM1 — Set Priority value for LLCP BLE message
  [3:0] BLEM0 — Set Priority value for Initiating (Connection Request Response) BLE message
0x10C BLE_BLEMPRIO1_REG 32-bit reset 0x30000000 (reset mask 0x7FFFFFFF) — Coexistence interface Priority 1 Register
  [31:28] BLEMDEFAULT — Set default priority value for other BLE message than those defined above
0x200 BLE_CNTL2_REG 32-bit reset 0x4 (reset mask 0x7FFFFFFF) — BLE Control Register 2
  [31:22] BLE_TRANSACTION_START — The value will be compared with the FINECNT in order to assert the BLE_TRANSACTION signal towards the COEX block. The deassertion of BLE_TRANSACTION is triggered by the deassertion of BLE_EVENT_IN_PROCESS. Refer also to BLE_TRANSACTION_MODE, BLE_TRANSACTION_SRC and BLE_PTI_SOURCE_SEL bitfields. If the desired distance from TX_EN/RX_EN is RADIO_PWRDN and TXRXPWRUP=max(TXPWRUP, RXPWRUP), then this bitfield must be set to (RADIO_PWRDN + TXRXPWRUP-1) if CS.FCNTOFFSET is "0", otherwise it must be set to (RADIO_PWRDN + TXRXPWRUP-1 - CS.FCNTOFFSET-1). Remark: BLE_EVENT_IN_PROCESS is controlled by the BLE_TIMGENCNTL_REG.PREFETCH_TIME, so the BLE_TRANSACTION_START should be less than the PREFETCH_TIME.
  [21] BLE_RSSI_SEL — 0: Select Peak-hold RSSI value (default). 1: Select current Average RSSI value.
  [20] WAKEUPLPSTAT ro — The status of the BLE_WAKEUP_LP_IRQ. The Interrupt Service Routine of BLE_WAKEUP_LP_IRQ should return only when the WAKEUPLPSTAT is cleared. Note that BLE_WAKEUP_LP_IRQ is automatically acknowledged after the power up of the Radio Subsystem, plus one Low Power Clock period.
  [19] SW_RPL_SPI — Keep to 0.
  [18] BB_ONLY — Keep to 0.
  [17] BLE_PTI_SOURCE_SEL — 0: Provide to COEX block the PTI value indicated by the Control Structure. Recommended value is "0". 1: Provide to COEX block the PTI value generated dynamically by the BLE core, which is based on the PTI of the Control Structure.
  [16] BLE_TRANSACTION_MODE — 0: Keep the BLE_TRANSACTION constant during the process of the current event, regadless of the state of PTI value. Recommended value is "0". 1: Create a one clock cycle of low period at the BLE_TRANSACTION whenever a change in the PTI value is detected. (refer also to BLE_PTI_SOURCE_SEL)
  [15] BLE_TRANSACTION_SRC — 0: Assert the BLE_TRANSACTION at the moment indicated by the BLE_TRANSACTION_START only if the PTI value is available at that moment, otherwise assert BLE_TRANSACTION at the next positive edge of TX_EN ot RX_EN. Recommended value is "0". 1: Assert the BLE_TRANSACTION at the moment indicated by the BLE_TRANSACTION_START, if during this moment the BLE_EVENT_IN_PROCESS is asserted, otherwise assert BLE_TRANSACTION at the next positive edge of TX_EN ot RX_EN. Useful when COEX_CTRL_REG[SEL_BLE_PTI]=0.
  [14:9] BLE_CLK_SEL — BLE Clock Select. Specifies the BLE master clock absolute frequency in MHz. Typical values are 16 and 8. Value depends on the selected XTAL frequency and the value of CLK_RADIO_REG[BLE_DIV] bitfield. For example, if XTAL oscillates at 16MHz and CLK_RADIO_REG[BLE_DIV] = 1 (divide by 2), then BLE master clock frequency is 8MHz and BLE_CLK_SEL should be set to value 8. The selected BLE master clock frequency (affected by BLE_DIV and BLE_CLK_SEL) must be modified and set only during the initialization time, i.e. before setting BLE_RWBTLECNTL_REG[RWBLE_EN] to 1. Refer also to BLE_RWBTLECONF_REG[CLK_SEL].
  [8] RADIO_PWRDN_ALLOW ro — This active high signal indicates when it is allowed for the BLE core (embedded in the Radio sub-System power domain) to be powered down. After the assertion of the BLE_DEEPSLCNTL_REG[DEEP_SLEEP_ON] a hardware sequence based on the Low Power clock will cause the assertion of RADIO_PWRDN_ALLOW. The RADIO_PWRDN_ALLOW will be cleared to "0" when the BLE core exits from the sleep state, i.e. when the BLE_SLP_IRQ will be asserted.
  [7] MON_LP_CLK ro — The SW can only write a "0" to this bit. Whenever a positive edge of the low power clock used by the BLE Timers is detected, then the HW will automatically set this bit to "1". This functionality will not work if BLE Timer is in reset state (refer to CLK_RADIO_REG[BLE_LP_RESET]). This bit can be used for SW synchronization, to debug the low power clock, etc.
  [6] BLE_CLK_STAT ro — 0: BLE uses low power clock 1: BLE uses master clock
  [5:4] BLE_DIAG_OVR_SEL — Effective only when BLE_CNTL2_REG[ BLE_DIAG_OVR ] is set to '1', providing the values of P1[0] and P1[2] diagnostic signals: P1[0] will provide the logical OR of all Cortex M0 IRQ lines, regadless of the BLE_DIAG_OVR_SEL value. P1[2] will provide the value according to the BLE_DIAG_OVR_SEL value: 00: "low_power_clk" free running clock. 01: "running_at_32k" status. 10: "cortex_deepsleep" status. 11: "deep_sleep_stat_32k" BLE core in sleep mode.
  [3] BLE_DIAG_OVR — 1: Overrule the P1[0] and P1[2] control signals PAD_LATCH_EN to always "1" and the direction to always "output". It can be used in combination with the BLE_CNTL2_REG[ BLE_DIAG_OVR_SEL ] to provide diagnostic signals on P1[0] and P1[2] even while the system is in power down state. 0: The PAD_LATCH_EN and direction of P1[0] and P1[2] pins are not overruled.
  [2] EMACCERRMSK — Exchange Memory Access Error Mask: When cleared to "0" the EM_ACC_ERR will not cause an BLE_ERROR_IRQ interrupt. When set to "1" an BLE_ERROR_IRQ will be generated as long as EM_ACC_ERR is "1".
  [1] EMACCERRACK wo — Exchange Memory Access Error Acknowledge. When the SW writes a "1" to this bit then the EMACCERRSTAT bit will be cleared. When the SW writes "0" it will have no affect. The read value is always "0".
  [0] EMACCERRSTAT ro — Exchange Memory Access Error Status: The bit is read-only and can be cleared only by writing a "1" at EMACCERRACK bitfield. This bit will be set to "1" by the hardware when the controller will access an EM page that is not mapped according to the EM_MAPPING value. When this bit is "1" then the BLE_ERROR_IRQ will be asserted as long as EMACCERRMSK is "1".
0x208 BLE_EM_BASE_REG 32-bit — Exchange Memory Base Register
  [16:10] BLE_EM_BASE_16_10 — The physical address on the system memory map of the base of the Exchange Memory.
0x20C BLE_DIAGCNTL2_REG 32-bit (reset mask 0x7FFFFFFF) — Debug use only
  [8n-25] DIAG{n}_EN (n=4..7) — 0: Disable diagnostic port 0 output. All outputs are set to 0x0. 1: Enable diagnostic port 0 output.
  [29:24] DIAG7 — Only relevant when DIAG7_EN = 1. Selection of the outputs that must be driven to the diagnostic port BLE_DIAG7.
  [21:16] DIAG6 — Only relevant when DIAG6_EN = 1. Selection of the outputs that must be driven to the diagnostic port BLE_DIAG6.
  [13:8] DIAG5 — Only relevant when DIAG5_EN= 1. Selection of the outputs that must be driven to the diagnostic port BLE_DIAG5.
  [5:0] DIAG4 — Only relevant when DIAG4_EN = 1. Selection of the outputs that must be driven to the diagnostic port BLE_DIAG4.
0x210 BLE_DIAGCNTL3_REG 32-bit (reset mask 0x7FFFFFFF) — Debug use only
  [4n+3] DIAG{n}_INV (n=0..7) — If set, then the specific diagnostic bit will be inverted.
  [4n+2:4n] DIAG{n}_BIT (n=0..7) — Selects which bit from the DIAG{n} word will be forwarded to bit {n} of the BLE DIagnostic Port.
